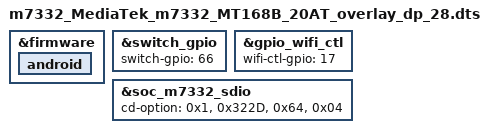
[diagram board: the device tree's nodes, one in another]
/dts-v1/;
/plugin/;

&firmware {
	android {
	};
};

&switch_gpio {
	switch-gpio = <66>;
};

&gpio_wifi_ctl {
	wifi-ctl-gpio = <17>;
};

&soc_m7332_sdio {
	cd-option = <0x1>, <0x322D>, <0x64>, <0x04>;
};
